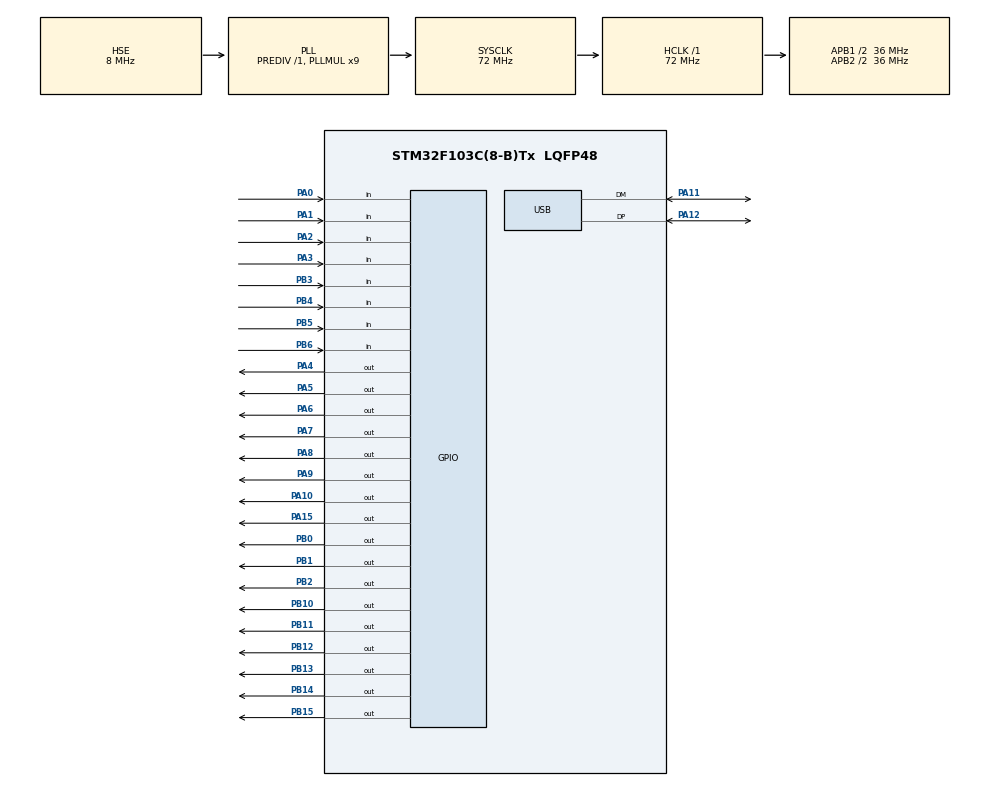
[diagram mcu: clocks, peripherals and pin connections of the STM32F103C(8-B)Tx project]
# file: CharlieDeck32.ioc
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Mcu.Family=STM32F1
Mcu.Name=STM32F103C(8-B)Tx
Mcu.Package=LQFP48
NVIC.PriorityGroup=NVIC_PRIORITYGROUP_4
NVIC.USB_LP_CAN1_RX0_IRQn=true\:0\:0\:false\:false\:true\:false\:true\:true
PA0-WKUP.Signal=GPIO_Input
PA1.Signal=GPIO_Input
PA10.GPIO_Speed=GPIO_SPEED_FREQ_HIGH
PA10.Signal=GPIO_Output
PA11.Mode=Device
PA11.Signal=USB_DM
PA12.Mode=Device
PA12.Signal=USB_DP
PA13.Mode=Serial_Wire
PA13.Signal=SYS_JTMS-SWDIO
PA14.Mode=Serial_Wire
PA14.Signal=SYS_JTCK-SWCLK
PA15.GPIO_Speed=GPIO_SPEED_FREQ_HIGH
PA15.Signal=GPIO_Output
PA2.Signal=GPIO_Input
PA3.Signal=GPIO_Input
PA4.GPIO_Speed=GPIO_SPEED_FREQ_HIGH
PA4.Signal=GPIO_Output
PA5.GPIO_Speed=GPIO_SPEED_FREQ_HIGH
PA5.Signal=GPIO_Output
PA6.GPIO_Speed=GPIO_SPEED_FREQ_HIGH
PA6.Signal=GPIO_Output
PA7.GPIO_Speed=GPIO_SPEED_FREQ_HIGH
PA7.Signal=GPIO_Output
PA8.GPIO_Speed=GPIO_SPEED_FREQ_HIGH
PA8.Signal=GPIO_Output
PA9.GPIO_Speed=GPIO_SPEED_FREQ_HIGH
PA9.Signal=GPIO_Output
PB0.GPIO_Speed=GPIO_SPEED_FREQ_HIGH
PB0.Signal=GPIO_Output
PB1.GPIO_Speed=GPIO_SPEED_FREQ_HIGH
PB1.Signal=GPIO_Output
PB10.GPIO_Speed=GPIO_SPEED_FREQ_HIGH
PB10.Signal=GPIO_Output
PB11.GPIO_Speed=GPIO_SPEED_FREQ_HIGH
PB11.Signal=GPIO_Output
PB12.GPIO_Speed=GPIO_SPEED_FREQ_HIGH
PB12.Signal=GPIO_Output
PB13.GPIO_Speed=GPIO_SPEED_FREQ_HIGH
PB13.Signal=GPIO_Output
PB14.GPIO_Speed=GPIO_SPEED_FREQ_HIGH
PB14.Signal=GPIO_Output
PB15.GPIO_Speed=GPIO_SPEED_FREQ_HIGH
PB15.Signal=GPIO_Output
PB2.GPIO_Speed=GPIO_SPEED_FREQ_HIGH
PB2.Signal=GPIO_Output
PB3.Signal=GPIO_Input
PB4.Signal=GPIO_Input
PB5.Signal=GPIO_Input
PB6.Signal=GPIO_Input
PD0-OSC_IN.Mode=HSE-External-Oscillator
PD0-OSC_IN.Signal=RCC_OSC_IN
PD1-OSC_OUT.Mode=HSE-External-Oscillator
PD1-OSC_OUT.Signal=RCC_OSC_OUT
ProjectManager.HeapSize=0x200
ProjectManager.StackSize=0x400
ProjectManager.TargetToolchain=CMake
RCC.AHBFreq_Value=72000000
RCC.APB1CLKDivider=RCC_HCLK_DIV2
RCC.APB1Freq_Value=36000000
RCC.APB1TimFreq_Value=72000000
RCC.APB2CLKDivider=RCC_HCLK_DIV2
RCC.APB2Freq_Value=36000000
RCC.APB2TimFreq_Value=72000000
RCC.HCLKFreq_Value=72000000
RCC.PLLMUL=RCC_PLL_MUL9
RCC.SYSCLKFreq_VALUE=72000000
RCC.SYSCLKSource=RCC_SYSCLKSOURCE_PLLCLK
RCC.USBFreq_Value=48000000
RCC.USBPrescaler=RCC_USBCLKSOURCE_PLL_DIV1_5
TIM1.Prescaler=0
USB_DEVICE.CLASS_NAME_FS=HID
USB_DEVICE.VirtualMode=Hid
USB_DEVICE.VirtualModeFS=Hid_FS
VP_TIM1_VS_ClockSourceINT.Mode=Internal
VP_TIM2_VS_ClockSourceINT.Mode=Internal
VP_TIM3_VS_ClockSourceINT.Mode=Internal
VP_TIM4_VS_ClockSourceINT.Mode=Internal
VP_USB_DEVICE_VS_USB_DEVICE_HID_FS.Mode=HID_FS
board=custom

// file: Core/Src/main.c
#include "main.h"
#include "tim.h"
#include "usb_device.h"
#include "gpio.h"

#include "charlieplex.h"
#include "games.h"

#define BIT_WIDTH_TYPE(type) (sizeof(type) * 8)

void SystemClock_Config(void);
void Poll_Buttons(GPIO_TypeDef **ButtonPorts, uint16_t *ButtonPins, uint8_t NumButtons, uint8_t PressState, uint8_t *clickMask, uint8_t *pressMask);
static inline void seed_rng();

// USB variables
GPIO_TypeDef *usb_enum_pin_port = GPIOA;
uint16_t usb_enum_pin = GPIO_PIN_15;

// LED Matrix variables
GPIO_TypeDef *matrix_ports[] = {
    GPIOA, GPIOA, GPIOA, GPIOB, GPIOB, GPIOB, GPIOB, GPIOB,
    GPIOB, GPIOB, GPIOB, GPIOB, GPIOA, GPIOA, GPIOA, GPIOA};
#define NUM_MATRIX_PORTS (sizeof(matrix_ports) / sizeof(matrix_ports[0]))

uint16_t matrix_pins[] = {
    GPIO_PIN_10, GPIO_PIN_9, GPIO_PIN_8, GPIO_PIN_15,
    GPIO_PIN_14, GPIO_PIN_13, GPIO_PIN_12, GPIO_PIN_11,
    GPIO_PIN_10, GPIO_PIN_2, GPIO_PIN_1, GPIO_PIN_0,
    GPIO_PIN_7, GPIO_PIN_6, GPIO_PIN_5, GPIO_PIN_4};
#define NUM_MATRIX_PINS (sizeof(matrix_pins) / sizeof(matrix_pins[0]))

#define NUM_ROWS_Y (NUM_MATRIX_PINS - 1)
#define NUM_COLUMNS_X (NUM_MATRIX_PINS)

uint8_t screen[NUM_ROWS_Y][NUM_COLUMNS_X] = {0};

// Button variables (External pull-up)
static GPIO_TypeDef *button_ports[8] = {
    GPIOB, // 1 = UP
    GPIOB, // 2 = DOWN
    GPIOB, // 4 = LEFT
    GPIOB, // 8 = RIGHT
    GPIOA, // 16 = C
    GPIOA, // 32 = A
    GPIOA, // 64 = D
    GPIOA  // 128 = B
};
static uint16_t button_pins[8] = {
    GPIO_PIN_4, // 1 = UP
    GPIO_PIN_5, // 2 = DOWN
    GPIO_PIN_3, // 4 = LEFT
    GPIO_PIN_6, // 8 = RIGHT
    GPIO_PIN_1, // 16 = C
    GPIO_PIN_2, // 32= A
    GPIO_PIN_3, // 64 = D
    GPIO_PIN_0  // 128 = B
};
#define NUM_BUTTON_PORTS (sizeof(button_ports) / sizeof(button_ports[0]))
#define NUM_BUTTON_PINS (sizeof(button_pins) / sizeof(button_pins[0]))

#define BUTTON_UP (1 << 0)    // 0x01
#define BUTTON_DOWN (1 << 1)  // 0x02
#define BUTTON_LEFT (1 << 2)  // 0x04
#define BUTTON_RIGHT (1 << 3) // 0x08
#define BUTTON_C (1 << 4)     // 0x10
#define BUTTON_A (1 << 5)     // 0x20
#define BUTTON_D (1 << 6)     // 0x40
#define BUTTON_B (1 << 7)     // 0x80

// Mode variables
typedef enum
{
  MODE_MAIN_MENU = 0,
  MODE_SNAKE = 1,
  MODE_PONG = 2,
  MODE_FLAPPY = 3,
  MODE_TETRIS = 4,
  MODE_SCORE = 5
} GameMode;

GameMode mode = MODE_MAIN_MENU;

int main(void)
{
  HAL_Init();
  SystemClock_Config();
  MX_TIM1_Init();
  MX_TIM2_Init();
  MX_TIM3_Init();
  MX_TIM4_Init();
  MX_GPIO_Init();
  MX_USB_DEVICE_Init();

  HAL_TIM_Base_Start(&htim1);
  HAL_TIM_Base_Start(&htim2);
  HAL_TIM_Base_Start(&htim3);
  HAL_TIM_Base_Start(&htim4);

  Charlieplex_Clear(matrix_ports, NUM_MATRIX_PORTS, matrix_pins, NUM_MATRIX_PINS);

  HAL_GPIO_WritePin(usb_enum_pin_port, usb_enum_pin, GPIO_PIN_SET); // Initialize USB

  static uint32_t time_now = 0;
  time_now = HAL_GetTick();

  int32_t score = 0;
  uint8_t clickMask = 0;
  uint8_t pressMask = 0;

  while (1)
  {
    Poll_Buttons(button_ports, button_pins, NUM_BUTTON_PORTS, GPIO_PIN_RESET, &clickMask, &pressMask);
    if (((clickMask & BUTTON_UP) || (clickMask & BUTTON_C)) && mode == MODE_MAIN_MENU)
    {
      seed_rng();
      mode = MODE_SNAKE;
    }
    else if (((clickMask & BUTTON_RIGHT) || (clickMask & BUTTON_B)) && mode == MODE_MAIN_MENU)
    {
      seed_rng();
      mode = MODE_PONG;
    }
    else if (((clickMask & BUTTON_DOWN) || (clickMask & BUTTON_A)) && mode == MODE_MAIN_MENU)
    {
      seed_rng();
      mode = MODE_FLAPPY;
    }
    else if (((clickMask & BUTTON_LEFT) || (clickMask & BUTTON_D)) && mode == MODE_MAIN_MENU)
    {
      seed_rng();
      mode = MODE_TETRIS;
    }

    switch (mode)
    {
    case MODE_MAIN_MENU:
      MainMenuMatrix(screen);
      break;
    case MODE_SNAKE:
      score = Play_Snake(screen, clickMask, HAL_GetTick());
      if (score != -1)
      {
        mode = MODE_SCORE;
        time_now = HAL_GetTick();
      }

      break;
    case MODE_PONG:
      score = Play_Pong(screen, pressMask, HAL_GetTick());
      if (score != -1)
      {
        mode = MODE_SCORE;
        time_now = HAL_GetTick();
      }

      break;
    case MODE_FLAPPY:
      score = Play_FlappyBird(screen, clickMask, HAL_GetTick());
      if (score != -4)
      {
        mode = MODE_SCORE;
        time_now = HAL_GetTick();
      }

      break;
    case MODE_TETRIS:
      Play_Tetris(screen, clickMask, HAL_GetTick());
      break;
    case MODE_SCORE:
      if (HAL_GetTick() - time_now < 3000)
      {
        ScoreMatrix(screen, score);
      }
      else
      {
        NVIC_SystemReset();
      }
      break;
    }
    Charlieplex_Display(matrix_ports, NUM_MATRIX_PORTS, matrix_pins, NUM_MATRIX_PINS, screen);
    clickMask = 0;
    pressMask = 0;
  }
}

/**
 * @brief Seeds the random number generator with the current time and the
 *        current counter value of timer 2. This should be called at the
 *        beginning of any game to ensure that the random numbers are
 *        different each time the game is played.
 */
static inline void seed_rng()
{
  srand(__HAL_TIM_GET_COUNTER(&htim2) ^ HAL_GetTick());
}

/**
 * @brief Polls an array of buttons, detects clicks and current press states.
 *
 * This function scans multiple buttons connected to GPIO pins, updates two bitmasks:
 * - **clickMask**: Bits set for buttons that transitioned from released to pressed
 *   during this polling cycle (rising edge detection).
 * - **pressMask**: Bits set for buttons that are currently pressed.
 *
 * @param[in]  ButtonPorts  Array of pointers to GPIO port structures for each button.
 * @param[in]  NumButtons   Number of buttons to scan (must be <= 8 for uint8_t masks).
 * @param[in]  ButtonPins   Array of GPIO pin numbers (HAL format) for each button.
 * @param[in]  PressState   Logical state representing a pressed button
 *                          (`GPIO_PIN_SET` or `GPIO_PIN_RESET`).
 * @param[out] clickMask     Pointer to a uint8_t that will store the click bitmask.
 *                          A bit is set if that button was released this cycle.
 * @param[out] pressMask     Pointer to a uint8_t that will store the press bitmask.
 *                          A bit is set if that button is currently pressed.
 *
 * @note Both bitmasks use bit position `i` for button index `i`.
 *       Example: If button 0 and 2 are pressed, pressMask = `0b00000101`.
 *
 * @warning NumButtons must not exceed 8 when using `uint8_t` _pressMasks. Increase the type
 *          if you need more buttons.
 *
 * @return None.
 */
void Poll_Buttons(GPIO_TypeDef **ButtonPorts, uint16_t *ButtonPins, uint8_t NumButtons, uint8_t PressState, uint8_t *clickMask, uint8_t *pressMask)
{
  if (NumButtons > BIT_WIDTH_TYPE(uint8_t))
  {
    *clickMask = 0;
    *pressMask = 0;
    return;
  }

  static uint8_t button_flags[BIT_WIDTH_TYPE(uint8_t)] = {0};
  uint8_t _clickMask = 0;
  uint8_t _pressMask = 0;

  for (uint8_t i = 0; i < NumButtons; i++)
  {
    GPIO_PinState state = HAL_GPIO_ReadPin(ButtonPorts[i], ButtonPins[i]);

    // Track continuous press state
    if (state == PressState)
    {
      _pressMask |= (1 << i);
    }

    // Detect click (rising edge)
    if (state == PressState && button_flags[i] == 0)
    {
      button_flags[i] = 1;
      _clickMask |= (1 << i);
    }
    else if (state != PressState && button_flags[i] == 1)
    {
      button_flags[i] = 0;
    }
  }

  *clickMask = _clickMask;
  *pressMask = _pressMask;
}

void SystemClock_Config(void)
{
  RCC_OscInitTypeDef RCC_OscInitStruct = {0};
  RCC_ClkInitTypeDef RCC_ClkInitStruct = {0};
  RCC_PeriphCLKInitTypeDef PeriphClkInit = {0};

  RCC_OscInitStruct.OscillatorType = RCC_OSCILLATORTYPE_HSE;
  RCC_OscInitStruct.HSEState = RCC_HSE_ON;
  RCC_OscInitStruct.HSEPredivValue = RCC_HSE_PREDIV_DIV1;
  RCC_OscInitStruct.HSIState = RCC_HSI_ON;
  RCC_OscInitStruct.PLL.PLLState = RCC_PLL_ON;
  RCC_OscInitStruct.PLL.PLLSource = RCC_PLLSOURCE_HSE;
  RCC_OscInitStruct.PLL.PLLMUL = RCC_PLL_MUL9;
  if (HAL_RCC_OscConfig(&RCC_OscInitStruct) != HAL_OK)
  {
    Error_Handler();
  }

  RCC_ClkInitStruct.ClockType = RCC_CLOCKTYPE_HCLK | RCC_CLOCKTYPE_SYSCLK | RCC_CLOCKTYPE_PCLK1 | RCC_CLOCKTYPE_PCLK2;
  RCC_ClkInitStruct.SYSCLKSource = RCC_SYSCLKSOURCE_PLLCLK;
  RCC_ClkInitStruct.AHBCLKDivider = RCC_SYSCLK_DIV1;
  RCC_ClkInitStruct.APB1CLKDivider = RCC_HCLK_DIV2;
  RCC_ClkInitStruct.APB2CLKDivider = RCC_HCLK_DIV2;

  if (HAL_RCC_ClockConfig(&RCC_ClkInitStruct, FLASH_LATENCY_2) != HAL_OK)
  {
    Error_Handler();
  }
  PeriphClkInit.PeriphClockSelection = RCC_PERIPHCLK_USB;
  PeriphClkInit.UsbClockSelection = RCC_USBCLKSOURCE_PLL_DIV1_5;
  if (HAL_RCCEx_PeriphCLKConfig(&PeriphClkInit) != HAL_OK)
  {
    Error_Handler();
  }
}

void Error_Handler(void)
{
  /* USER CODE BEGIN Error_Handler_Debug */
  /* User can add his own implementation to report the HAL error return state */
  __disable_irq();
  NVIC_SystemReset();
  while (1)
  {
  }
  /* USER CODE END Error_Handler_Debug */
}
